# ESP32-S31 register map
Vendor: ESPRESSIF SYSTEMS (SHANGHAI) CO., LTD.; Series: ESP32 S-Series; File version: 1
CPU: RV32IMAFC r0p0, little endian, no MPU, FPU, 0 interrupt priority bits
Address unit: 32 bits
Registers are 32-bit, read-write, reset 0x0 unless marked. A register's access mark holds for its fields unless they carry their own. Offsets are from the block's base; [hi:lo] are bit positions; lines under a group give offsets from that group; {n}, {i} and the like mark numbered series.

## ASSIST_DEBUG — ASSIST_DEBUG (BUS_MONITOR) Peripheral
Base 0x2D002000
{0x0+0x88*i} CPU{i} (i=0..1) group — Cluster CPU{i}, containing CORE_?_MONTR_ENA, CORE_?_INTR_RAW, CORE_?_INTR_ENA, CORE_?_INTR_CLR, CORE_?_AREA_DRAM0_0_MIN, CORE_?_AREA_DRAM0_0_MAX, CORE_?_AREA_DRAM0_1_MIN, CORE_?_AREA_DRAM0_1_MAX, CORE_?_AREA_PIF_0_MIN, CORE_?_AREA_PIF_0_MAX, CORE_?_AREA_PIF_1_MIN, CORE_?_AREA_PIF_1_MAX, CORE_?_AREA_PC, CORE_?_AREA_SP, CORE_?_SP_MIN, CORE_?_SP_MAX, CORE_?_SP_PC, CORE_?_RCD_EN, CORE_?_RCD_PDEBUGPC, CORE_?_RCD_PDEBUGSP, CORE_?_IRAM0_EXCEPTION_MONITOR_0, CORE_?_DRAM0_EXCEPTION_MONITOR_0, CORE_?_DRAM0_EXCEPTION_MONITOR_1, CORE_?_DRAM0_EXCEPTION_MONITOR_2, CORE_?_LASTPC_BEFORE_EXCEPTION, CORE_?_DEBUG_MODE, CORE_?_TRACE_LOCKUP_CAUSE_0, CORE_?_TRACE_LOCKUP_TVAL_0, CORE_?_TRACE_LOCKUP_IADDR_0, CORE_?_TRACE_LOCKUP_PRIV_0, CORE_?_TRACE_LOCKUP_CAUSE_1, CORE_?_TRACE_LOCKUP_TVAL_1, CORE_?_TRACE_LOCKUP_IADDR_1, CORE_?_TRACE_LOCKUP_PRIV_1
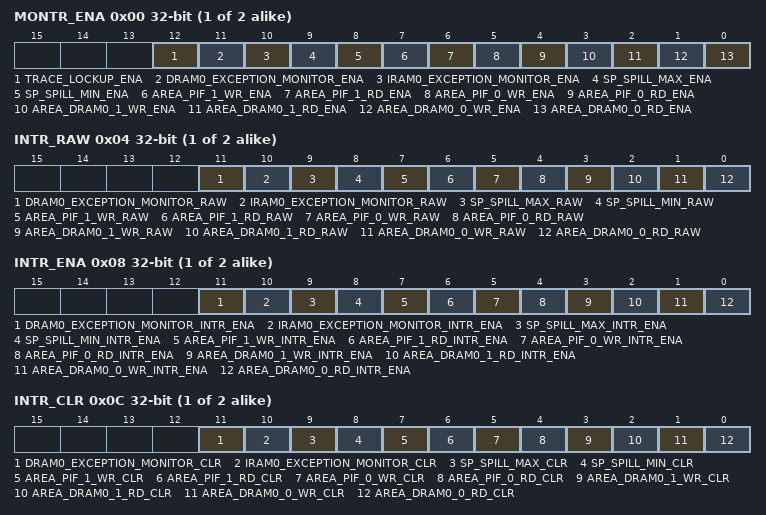
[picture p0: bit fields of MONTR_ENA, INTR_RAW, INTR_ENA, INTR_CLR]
  0x00 MONTR_ENA — core0 monitor enable configuration register
    [12] TRACE_LOCKUP_ENA — trace lockup monitor enbale
    [11] DRAM0_EXCEPTION_MONITOR_ENA — DBUS busy monitor enbale
    [10] IRAM0_EXCEPTION_MONITOR_ENA — IBUS busy monitor enable
    [9] SP_SPILL_MAX_ENA — Configures whether to monitor SP exceeding the upper bound address of SP monitored region.\\ 0: Not Monitor\\ 1: Monitor\\
    [8] SP_SPILL_MIN_ENA — Configures whether to monitor SP exceeding the lower bound address of SP monitored region.\\ 0: Not Monitor\\ 1: Monitor\\
    [7] AREA_PIF_1_WR_ENA — Configures whether to monitor write operations in region 1 by the Peripheral bus.\\ 0: Not Monitor\\ 1: Monitor\\
    [6] AREA_PIF_1_RD_ENA — Configures whether to monitor read operations in region 1 by the Peripheral bus.\\ 0: Not Monitor\\ 1: Monitor\\
    [5] AREA_PIF_0_WR_ENA — Configures whether to monitor write operations in region 0 by the Peripheral bus.\\ 0: Not Monitor\\ 1: Monitor\\
    [4] AREA_PIF_0_RD_ENA — Configures whether to monitor read operations in region 0 by the Peripheral bus.\\ 0: Not Monitor\\ 1: Monitor\\
    [3] AREA_DRAM0_1_WR_ENA — Configures whether to monitor write operations in region 1 by the Data bus.\\ 0: Not Monitor\\ 1: Monitor\\
    [2] AREA_DRAM0_1_RD_ENA — Configures whether to monitor read operations in region 1 by the Data bus.\\ 0: Not Monitor\\ 1: Monitor\\
    [1] AREA_DRAM0_0_WR_ENA — Configures whether to monitor write operations in region 0 by the Data bus.\\ 0: Not monitor\\ 1: Monitor\\
    [0] AREA_DRAM0_0_RD_ENA — Configures whether to monitor read operations in region 0 by the Data bus. \\ 0: Not monitor\\ 1: Monitor\\
  0x04 INTR_RAW ro — core0 monitor interrupt status register
    [11] DRAM0_EXCEPTION_MONITOR_RAW — DBUS busy monitor initerrupt status
    [10] IRAM0_EXCEPTION_MONITOR_RAW — IBUS busy monitor interrupt status
    [9] SP_SPILL_MAX_RAW — The raw interrupt status of SP exceeding the upper bound address of SP monitored region.
    [8] SP_SPILL_MIN_RAW — The raw interrupt status of SP exceeding the lower bound address of SP monitored region.
    [7] AREA_PIF_1_WR_RAW — The raw interrupt status of write operations in region 1 by Peripheral bus.
    [6] AREA_PIF_1_RD_RAW — The raw interrupt status of read operations in region 1 by Peripheral bus.
    [5] AREA_PIF_0_WR_RAW — The raw interrupt status of write operations in region 0 by Peripheral bus.
    [4] AREA_PIF_0_RD_RAW — The raw interrupt status of read operations in region 0 by Peripheral bus.
    [3] AREA_DRAM0_1_WR_RAW — The raw interrupt status of write operations in region 1 by Data bus.
    [2] AREA_DRAM0_1_RD_RAW — The raw interrupt status of read operations in region 1 by Data bus.
    [1] AREA_DRAM0_0_WR_RAW — The raw interrupt status of write operations in region 0 by Data bus.
    [0] AREA_DRAM0_0_RD_RAW — The raw interrupt status of read operations in region 0 by Data bus.
  0x08 INTR_ENA — core0 monitor interrupt enable register
    [11] DRAM0_EXCEPTION_MONITOR_INTR_ENA — DBUS busy monitor interrupt enbale
    [10] IRAM0_EXCEPTION_MONITOR_INTR_ENA — IBUS busy monitor interrupt enable
    [9] SP_SPILL_MAX_INTR_ENA — Core0 stackpoint overflow monitor interrupt enable
    [8] SP_SPILL_MIN_INTR_ENA — Core0 stackpoint underflow monitor interrupt enable
    [7] AREA_PIF_1_WR_INTR_ENA — Core0 PIF area1 write monitor interrupt enable
    [6] AREA_PIF_1_RD_INTR_ENA — Core0 PIF area1 read monitor interrupt enable
    [5] AREA_PIF_0_WR_INTR_ENA — Core0 PIF area0 write monitor interrupt enable
    [4] AREA_PIF_0_RD_INTR_ENA — Core0 PIF area0 read monitor interrupt enable
    [3] AREA_DRAM0_1_WR_INTR_ENA — Core0 dram0 area1 write monitor interrupt enable
    [2] AREA_DRAM0_1_RD_INTR_ENA — Core0 dram0 area1 read monitor interrupt enable
    [1] AREA_DRAM0_0_WR_INTR_ENA — Core0 dram0 area0 write monitor interrupt enable
    [0] AREA_DRAM0_0_RD_INTR_ENA — Core0 dram0 area0 read monitor interrupt enable
  0x0C INTR_CLR wo — core0 monitor interrupt clear register
    [11] DRAM0_EXCEPTION_MONITOR_CLR — DBUS busy monitor interrupt clr
    [10] IRAM0_EXCEPTION_MONITOR_CLR — IBUS busy monitor interrupt clr
    [9] SP_SPILL_MAX_CLR — Write 1 to clear the interrupt for SP exceeding the upper bound address of SP monitored region.
    [8] SP_SPILL_MIN_CLR — Write 1 to clear the interrupt for SP exceeding the lower bound address of SP monitored region.
    [7] AREA_PIF_1_WR_CLR — Write 1 to clear the interrupt for write operations in region 1 by Peripheral bus.
    [6] AREA_PIF_1_RD_CLR — Write 1 to clear the interrupt for read operations in region 1 by Peripheral bus.
    [5] AREA_PIF_0_WR_CLR — Write 1 to clear the interrupt for write operations in region 0 by Peripheral bus.
    [4] AREA_PIF_0_RD_CLR — Write 1 to clear the interrupt for read operations in region 0 by Peripheral bus.
    [3] AREA_DRAM0_1_WR_CLR — Write 1 to clear the interrupt for write operations in region 1 by Data bus.
    [2] AREA_DRAM0_1_RD_CLR — Write 1 to clear the interrupt for read operations in region 1 by Data bus.
    [1] AREA_DRAM0_0_WR_CLR — Write 1 to clear the interrupt for write operations in region 0 by Data bus.
    [0] AREA_DRAM0_0_RD_CLR — Write 1 to clear the interrupt for read operations in region 0 by Data bus.
  0x10 AREA_DRAM0_0_MIN reset 0xFFFFFFFF — Configures lower boundary address of region 0 monitored on Data bus
    [31:0] AREA_DRAM0_0_MIN — Configures the lower bound address of Data bus region 0.
  0x14 AREA_DRAM0_0_MAX — Configures upper boundary address of region 0 monitored on Data bus
    [31:0] AREA_DRAM0_0_MAX — Configures the upper bound address of Data bus region 0.
  0x18 AREA_DRAM0_1_MIN reset 0xFFFFFFFF — Configures lower boundary address of region 1 monitored on Data bus
    [31:0] AREA_DRAM0_1_MIN — Configures the lower bound address of Data bus region 1.
  0x1C AREA_DRAM0_1_MAX — Configures upper boundary address of region 1 monitored on Data bus
    [31:0] AREA_DRAM0_1_MAX — Configures the upper bound address of Data bus region 1.
  0x20 AREA_PIF_0_MIN reset 0xFFFFFFFF — Configures lower boundary address of region 0 monitored on Peripheral bus
    [31:0] AREA_PIF_0_MIN — Configures the lower bound address of Peripheral bus region 0.
  0x24 AREA_PIF_0_MAX — Configures upper boundary address of region 0 monitored on Peripheral bus
    [31:0] AREA_PIF_0_MAX — Configures the upper bound address of Peripheral bus region 0.
  0x28 AREA_PIF_1_MIN reset 0xFFFFFFFF — Configures lower boundary address of region 1 monitored on Peripheral bus
    [31:0] AREA_PIF_1_MIN — Configures the lower bound address of Peripheral bus region 1.
  0x2C AREA_PIF_1_MAX — Configures upper boundary address of region 1 monitored on Peripheral bus
    [31:0] AREA_PIF_1_MAX — Configures the upper bound address of Peripheral bus region 1.
  0x30 AREA_PC ro — Region monitoring HP CPU PC status register
    [31:0] AREA_PC — Represents the PC value when an interrupt is triggered during region monitoring.
  0x34 AREA_SP ro — Region monitoring HP CPU SP status register
    [31:0] AREA_SP — Represents the SP value when an interrupt is triggered during region monitoring.
  0x38 SP_MIN — Configures stack monitoring lower boundary address
    [31:0] SP_MIN — Configures the lower bound address of SP.
  0x3C SP_MAX reset 0xFFFFFFFF — Configures stack monitoring upper boundary address
    [31:0] SP_MAX — Configures the upper bound address of SP.
  0x40 SP_PC ro — Stack monitoring HP CPU PC status register
    [31:0] SP_PC — Represents the PC value during stack monitoring.
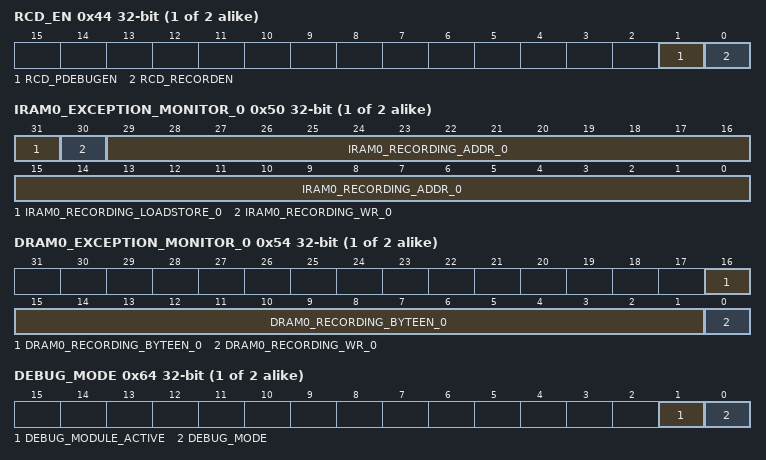
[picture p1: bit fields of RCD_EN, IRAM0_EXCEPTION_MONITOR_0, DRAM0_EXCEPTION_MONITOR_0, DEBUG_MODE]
  0x44 RCD_EN — HP CPU PC logging enable register
    [1] RCD_PDEBUGEN — Configures whether to enable HP CPU debugging.\\ 0: Disable\\ 1: HP CPU outputs PC\\
    [0] RCD_RECORDEN — Configures whether to enable PC and SP logging.\\ 0: Disable\\ 1: ASSIST_DEBUG_CORE_0_RCD_PDEBUGPC_REG starts to record PC in real time, BUS_MONITOR_CORE_0_RCD_PDEBUGSP_REG starts to record SP in real time\\
  0x48 RCD_PDEBUGPC ro — PC logging register
    [31:0] RCD_PDEBUGPC — Represents the PC value at HP CPU reset.
  0x4C RCD_PDEBUGSP ro — PC logging register
    [31:0] RCD_PDEBUGSP — Represents SP.
  0x50 IRAM0_EXCEPTION_MONITOR_0 ro — exception monitor status register0
    [31] IRAM0_RECORDING_LOADSTORE_0 — reg_core_0_iram0_recording_loadstore_0
    [30] IRAM0_RECORDING_WR_0 — reg_core_0_iram0_recording_wr_0
    [29:0] IRAM0_RECORDING_ADDR_0 — reg_core_0_iram0_recording_addr_0
  0x54 DRAM0_EXCEPTION_MONITOR_0 ro — exception monitor status register2
    [16:1] DRAM0_RECORDING_BYTEEN_0 — reg_core_0_dram0_recording_byteen_0
    [0] DRAM0_RECORDING_WR_0 — reg_core_0_dram0_recording_wr_0
  0x58 DRAM0_EXCEPTION_MONITOR_1 ro — exception monitor status register3
    [27:0] DRAM0_RECORDING_ADDR_0 — reg_core_0_dram0_recording_addr_0
  0x5C DRAM0_EXCEPTION_MONITOR_2 ro — exception monitor status register4
    [31:0] DRAM0_RECORDING_PC_0 — reg_core_0_dram0_recording_pc_0
  0x60 LASTPC_BEFORE_EXCEPTION ro — cpu status register
    [31:0] LASTPC_BEFORE_EXC — Represents the PC of the last command before the HP CPU enters exception.
  0x64 DEBUG_MODE ro — cpu status register
    [1] DEBUG_MODULE_ACTIVE — Represents the status of the RISC-V CPU (HP CPU) debug module.\\ 1: Active status\\ Other: Inactive status\\
    [0] DEBUG_MODE — Represents whether RISC-V CPU (HP CPU) is in debugging mode.\\ 1: In debugging mode\\ 0: Not in debugging mode\\
  0x68 TRACE_LOCKUP_CAUSE_0 ro — TRACE lockup cause logging register
    [11:0] TRACE_LOCKUP_RECORDING_CAUSE_0 — Represents the latest lockup cause
  0x6C TRACE_LOCKUP_TVAL_0 ro — TRACE lockup tval logging register
    [31:0] TRACE_LOCKUP_RECORDING_TVAL_0 — Represents the latest lockup tval
  0x70 TRACE_LOCKUP_IADDR_0 ro — TRACE lockup iaddr logging register
    [31:0] TRACE_LOCKUP_RECORDING_IADDR_0 — Represents the latest lockup iaddr
  0x74 TRACE_LOCKUP_PRIV_0 ro — TRACE lockup priv logging register
    [1:0] TRACE_LOCKUP_RECORDING_PRIV_0 — Represents the latest lockup priv
  0x78 TRACE_LOCKUP_CAUSE_1 ro — TRACE lockup cause logging register
    [11:0] TRACE_LOCKUP_RECORDING_CAUSE_1 — Represents the last lockup cause
  0x7C TRACE_LOCKUP_TVAL_1 ro — TRACE lockup tval logging register
    [31:0] TRACE_LOCKUP_RECORDING_TVAL_1 — Represents the last lockup tval
  0x80 TRACE_LOCKUP_IADDR_1 ro — TRACE lockup iaddr logging register
    [31:0] TRACE_LOCKUP_RECORDING_IADDR_1 — Represents the last lockup iaddr
  0x84 TRACE_LOCKUP_PRIV_1 ro — TRACE lockup priv logging register
    [1:0] TRACE_LOCKUP_RECORDING_PRIV_1 — Represents the last lockup priv
0x110 CORE_X_IRAM0_DRAM0_EXCEPTION_MONITOR_0 — exception monitor status register
  [19:0] CORE_X_IRAM0_DRAM0_LIMIT_CYCLE_0 — reg_core_x_iram0_dram0_limit_cycle_0
0x114 CLOCK_GATE reset 0x1 — Register clock control
  [0] CLK_EN — Configures whether to enable the register clock gating. \\ 0: Disable\\ 1: Enable\\
0x3FC DATE reset 0x2109130 — Version control register
  [27:0] DATE — version register
